# M0519AE_v1 register map
File version: 1.0
Registers are 32-bit, read-write, reset 0x0 unless marked. A register's access mark holds for its fields unless they carry their own. Offsets are from the block's base; [hi:lo] are bit positions; 'fields as' and 'values as' point back to an identical list.

## ACMP — ACMP Register Map
Base 0x400D0000
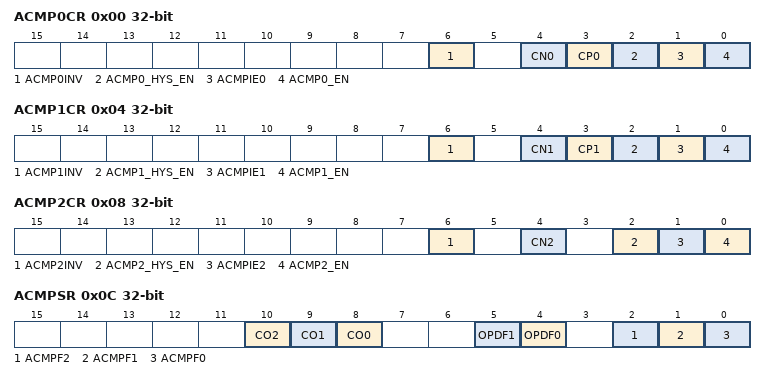
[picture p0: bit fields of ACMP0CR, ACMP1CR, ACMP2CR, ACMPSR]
0x00 ACMP0CR — Analog Comparator 0 Control Register
  [6] ACMP0INV — Analog Comparator 0 Output Inverse Select
    0=The comparator output inverse function Disabled; 1=The comparator output inverse function Enabled
  [4] CN0 — Analog Comparator 0 Negative Input Select
    0=The comparator reference pin P8.3/ACMP0_N is selected as the negative comparator input; 1=The internal band-gap voltage (VBG) is selected as the negative comparator input
  [3] CP0 — Analog Comparator 0 Positive Input Select
    0=The comparator reference pin P8.4/ACMP0_P is selected as the positive comparator input; 1=The internal OP amplifier 0 output is selected as the positive comparator input
  [2] ACMP0_HYS_EN — CMP Hysteresis Enable Bit
    0=Hysteresis function Disabled; 1=Hysteresis function Enabled
  [1] ACMPIE0 — Analog Comparator 0 Interrupt Enable Bit
    0=Interrupt function Disabled; 1=Interrupt function Enabled
  [0] ACMP0_EN — Analog Comparator 0 Enable Bit
    0=Analog comparator Disabled; 1=Analog comparator Enabled
0x04 ACMP1CR — Analog Comparator 1 Control Register
  [6] ACMP1INV — Analog Comparator 1 Output Inverse Select
    values as ACMP0CR.ACMP0INV
  [4] CN1 — Analog Comparator 1 Negative Input Select
    0=The comparator reference pin P6.4/ACMP1_N is selected as the negative comparator input; 1=The internal band-gap voltage (VBG) is selected as the negative comparator input
  [3] CP1 — Analog Comparator 1 Positive Input Select
    0=The comparator reference pin P6.5/ACMP1_P is selected as the positive comparator input; 1=The internal OP amplifier 1 output is selected as the positive comparator input
  [2] ACMP1_HYS_EN — CMP Hysteresis Enable Bit
    values as ACMP0CR.ACMP0_HYS_EN
  [1] ACMPIE1 — Analog Comparator 1 Interrupt Enable Bit
    0=Interrupt function Disabled; 1=Interrupt function Enabled
  [0] ACMP1_EN — Analog Comparator 1 Enable Bit
    0=Analog comparator Disabled; 1=Analog comparator Enabled
0x08 ACMP2CR — Analog Comparator 2 Control Register
  [6] ACMP2INV — Analog Comparator 2 Output Inverse Select
    values as ACMP0CR.ACMP0INV
  [4] CN2 — Analog Comparator 2 Negative Input Select
    0=The comparator reference pin P7.4/ACMP2_N is selected as the negative comparator input; 1=The internal band-gap voltage (VBG) is selected as the negative comparator input
  [2] ACMP2_HYS_EN — CMP Hysteresis Enable Bit
    values as ACMP0CR.ACMP0_HYS_EN
  [1] ACMPIE2 — Analog Comparator 2 Interrupt Enable Bit
    0=Interrupt function Disabled; 1=Interrupt function Enabled
  [0] ACMP2_EN — Analog Comparator 2 Enable Bit
    0=Analog comparator Disabled; 1=Analog comparator Enabled
0x0C ACMPSR — Analog Comparator Status Register
  [10] CO2 — Compare 2 Output
  [9] CO1 — Compare 1 Output
  [8] CO0 — Compare 0 Output
  [5] OPDF1 — OP Amplifier 1 Schmitt Trigger Digital Output Interrupt Flag. OPDF1 interrupt flag is set by hardware whenever the OP amplifier 1 Schmitt trigger non-inverting buffer digital output changes state. Note: This bit is remapping from OPASR[5] and writing 1 to ACMPSR[5] or OPASR[5] can clear this bit.
  [4] OPDF0 — OP Amplifier 0 Schmitt Trigger Digital Output Interrupt Flag. OPDF0 interrupt flag is set by hardware whenever the OP amplifier 0 Schmitt trigger non-inverting buffer digital output changes state. Note: This bit is remapping from OPASR[4] and writing 1 to ACMPSR[4] or OPASR[4] can clear this bit.
  [2] ACMPF2 — Compare 2 Flag. This bit is set by hardware whenever the comparator 2 output changes state. This will cause an interrupt if ACMP2CR[1] is set to 1. Write 1 to clear this bit to 0.
  [1] ACMPF1 — Compare 1 Flag. This bit is set by hardware whenever the comparator 1 output changes state. This will cause an interrupt if ACMP1CR[1] is set to 1. Write 1 to clear this bit to 0.
  [0] ACMPF0 — Compare 0 Flag. This bit is set by hardware whenever the comparator 0 output changes state. This will cause an interrupt if ACMP0CR[1] is set to 1. Write 1 to clear this bit to 0.
